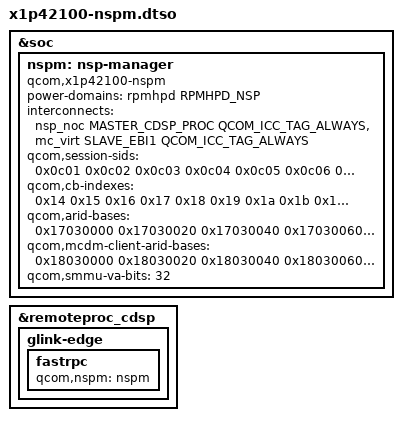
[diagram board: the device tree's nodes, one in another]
// SPDX-License-Identifier: BSD-3-Clause

#include <dt-bindings/interconnect/qcom,icc.h>
#include <dt-bindings/interconnect/qcom,x1e80100-rpmh.h>
#include <dt-bindings/power/qcom,rpmhpd.h>

/dts-v1/;
/plugin/;

&soc {
	nspm: nsp-manager {
		compatible = "qcom,x1p42100-nspm";

		power-domains = <&rpmhpd RPMHPD_NSP>;

		interconnects = <&nsp_noc MASTER_CDSP_PROC QCOM_ICC_TAG_ALWAYS
				 &mc_virt SLAVE_EBI1 QCOM_ICC_TAG_ALWAYS>;

		qcom,session-sids = <0x0c01 0x0c02 0x0c03 0x0c04
				      0x0c05 0x0c06 0x0c07 0x0c08
				      0x0c0c 0x0c0d 0x0c0e 0x0c0f>;
		qcom,cb-indexes = <0x14 0x15 0x16 0x17
				    0x18 0x19 0x1a 0x1b
				    0x1c 0x1d 0x1e 0x1f>;
		qcom,arid-bases = <0x17030000 0x17030020
				    0x17030040 0x17030060
				    0x17030080 0x170300a0
				    0x170300c0 0x170300e0
				    0x17030100 0x17030120
				    0x17030140 0x17030160>;
		qcom,mcdm-client-arid-bases = <0x18030000 0x18030020
						0x18030040 0x18030060
						0x18030080 0x180300a0
						0x180300c0 0x180300e0
						0x18030100 0x18030120
						0x18030140 0x18030160>;
		qcom,smmu-va-bits = <32>;
	};
};

&remoteproc_cdsp {
	glink-edge {
		fastrpc {
			qcom,nspm = <&nspm>;
		};
	};
};
